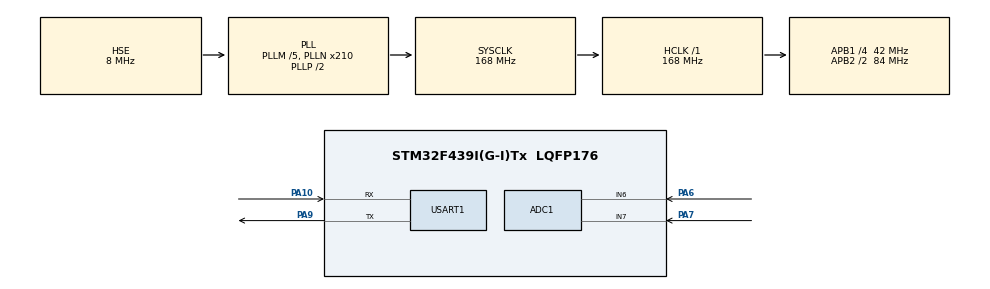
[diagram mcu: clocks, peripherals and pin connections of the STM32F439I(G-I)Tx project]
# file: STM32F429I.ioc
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ADC1.Channel-0\#ChannelRegularConversion=ADC_CHANNEL_6
ADC1.Channel-1\#ChannelRegularConversion=ADC_CHANNEL_7
ADC1.ClockPrescaler=ADC_CLOCKPRESCALER_PCLK_DIV4
ADC1.ContinuousConvMode=ENABLE
ADC1.DMAContinuousRequests=ENABLE
ADC1.DataAlign=ADC_DATAALIGN_RIGHT
ADC1.DiscontinuousConvMode=DISABLE
ADC1.EOCSelection=EOC_SINGLE_CONV
ADC1.EnableAnalogWatchDog=false
ADC1.ExternalTrigConvEdge=ADC_EXTERNALTRIGCONVEDGE_NONE
ADC1.InjNumberOfConversion=0
ADC1.NbrOfConversion=2
ADC1.NbrOfConversionFlag=1
ADC1.Rank-0\#ChannelRegularConversion=1
ADC1.Rank-1\#ChannelRegularConversion=2
ADC1.Resolution=ADC_RESOLUTION12b
ADC1.SamplingTime-0\#ChannelRegularConversion=ADC_SAMPLETIME_3CYCLES
ADC1.SamplingTime-1\#ChannelRegularConversion=ADC_SAMPLETIME_3CYCLES
ADC1.ScanConvMode=ENABLE
ADC1.master=1
Dma.ADC1.0.Channel=DMA_CHANNEL_0
Dma.ADC1.0.Direction=DMA_PERIPH_TO_MEMORY
Dma.ADC1.0.FIFOMode=DMA_FIFOMODE_DISABLE
Dma.ADC1.0.FIFOThreshold=DMA_FIFO_THRESHOLD_FULL
Dma.ADC1.0.Instance=DMA2_Stream0
Dma.ADC1.0.MemBurst=DMA_MBURST_SINGLE
Dma.ADC1.0.MemDataAlignment=DMA_MDATAALIGN_HALFWORD
Dma.ADC1.0.MemInc=DMA_MINC_ENABLE
Dma.ADC1.0.Mode=DMA_CIRCULAR
Dma.ADC1.0.PeriphBurst=DMA_PBURST_SINGLE
Dma.ADC1.0.PeriphDataAlignment=DMA_PDATAALIGN_HALFWORD
Dma.ADC1.0.PeriphInc=DMA_PINC_DISABLE
Dma.ADC1.0.Priority=DMA_PRIORITY_VERY_HIGH
Dma.Request0=ADC1
Mcu.Family=STM32F4
Mcu.Name=STM32F439I(G-I)Tx
Mcu.Package=LQFP176
NVIC.DMA2_Stream0_IRQn=true\:0\:0\:false
NVIC.PriorityGroup=NVIC_PRIORITYGROUP_4
PA10.Mode=Asynchronous
PA10.Signal=USART1_RX
PA6.Signal=ADCx_IN6
PA7.Signal=ADCx_IN7
PA9.Mode=Asynchronous
PA9.Signal=USART1_TX
PH0/OSC_IN.Mode=HSE-External-Oscillator
PH0/OSC_IN.Signal=RCC_OSC_IN
PH1/OSC_OUT.Mode=HSE-External-Oscillator
PH1/OSC_OUT.Signal=RCC_OSC_OUT
ProjectManager.TargetToolchain=MDK-ARM V5
RCC.48MHZClocksFreq_Value=84000000
RCC.AHBFreq_Value=168000000
RCC.APB1CLKDivider=RCC_HCLK_DIV4
RCC.APB1Freq_Value=42000000
RCC.APB1TimFreq_Value=84000000
RCC.APB2CLKDivider=RCC_HCLK_DIV2
RCC.APB2Freq_Value=84000000
RCC.APB2TimFreq_Value=168000000
RCC.CortexFreq_Value=168000000
RCC.HCLKFreq_Value=168000000
RCC.HSE_VALUE=8000000
RCC.HSI_VALUE=16000000
RCC.LSE_VALUE=32768
RCC.PLLM=5
RCC.PLLN=210
RCC.PLLSourceVirtual=RCC_PLLSOURCE_HSE
RCC.SYSCLKFreq_VALUE=168000000
RCC.SYSCLKSource=RCC_SYSCLKSOURCE_PLLCLK
RCC.VCOOutputFreq_Value=336000000
SH.ADCx_IN6.0=ADC1_IN6,IN6
SH.ADCx_IN7.0=ADC1_IN7,IN7
board=STM32F429I

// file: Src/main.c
/**
  ******************************************************************************
	*
  * File Name         	: main.c
  * Description        	: Main program body
	* Experimental 			: Flame Sensor                            	*
	* Connect      				: USART 1, PA9(TX)- RX TTL, PA10(RX)-TX TTL
  * 115200 BAUD, 8 Data Bits, None Parity, 1 Stop Bit, None Flow Control

	* Flame Sensor DOUT	- PA7
	* Flame Sensor AOUT	- PA6

  *******************************************************************************/

#include "stm32f4xx_hal.h"
#include "adc.h"
#include "dma.h"
#include "usart.h"
#include "gpio.h"
#include <math.h>

void SystemClock_Config(void);

/* USER CODE BEGIN PFP */
/* Private function prototypes -----------------------------------------------*/

/* USER CODE END PFP */

int main(void)
{

  /* USER CODE BEGIN 1 */
	uint16_t ADC_Value[100];
	  /* USER CODE END 1 */

  /* MCU Configuration----------------------------------------------------------*/

  /* Reset of all peripherals, Initializes the Flash interface and the Systick. */
  HAL_Init();

  /* Configure the system clock */
  SystemClock_Config();

  /* Initialize all configured peripherals */
  MX_GPIO_Init();
  MX_DMA_Init();
  MX_ADC1_Init();
  MX_USART1_UART_Init();

  /* USER CODE BEGIN 2 */
	/*##-1- Start the conversion process and enable interrupt ##################*/
  HAL_ADC_Start_DMA(&hadc1, (uint32_t*)&ADC_Value, 100);

  /* USER CODE END 2 */
	double AD_value;
  /* Infinite loop */
  /* USEdouble AD_value;R CODE BEGIN WHILE */
  while (1)
  {
  /* USER CODE END WHILE */

		HAL_ADC_Start(&hadc1);
		AD_value = HAL_ADC_GetValue(&hadc1);
		if(HAL_GPIO_ReadPin(GPIOA, GPIO_PIN_7) == GPIO_PIN_SET )
		{
			HAL_GPIO_WritePin(LED1_GPIO_Port, LED1_Pin,GPIO_PIN_RESET );
			printf("Flame Sensor no detected!\r\n");

		}
		else
		{
			HAL_GPIO_WritePin(LED1_GPIO_Port, LED1_Pin,GPIO_PIN_SET );
			printf("Flame Sensor detected\r\n");

    /* USER CODE BEGIN 3 */
  }

			float voltage = (AD_value / 4096.0) * 3;
			printf("ADC voltage = %2fV \r\n", voltage);
			HAL_Delay(20);   /* delay 2000ms */
}

}

/** System Clock Configuration
*/
void SystemClock_Config(void)
{

  RCC_OscInitTypeDef RCC_OscInitStruct;
  RCC_ClkInitTypeDef RCC_ClkInitStruct;

  __PWR_CLK_ENABLE();

  __HAL_PWR_VOLTAGESCALING_CONFIG(PWR_REGULATOR_VOLTAGE_SCALE1);

  RCC_OscInitStruct.OscillatorType = RCC_OSCILLATORTYPE_HSE;
  RCC_OscInitStruct.HSEState = RCC_HSE_ON;
  RCC_OscInitStruct.PLL.PLLState = RCC_PLL_ON;
  RCC_OscInitStruct.PLL.PLLSource = RCC_PLLSOURCE_HSE;
  RCC_OscInitStruct.PLL.PLLM = 5;
  RCC_OscInitStruct.PLL.PLLN = 210;
  RCC_OscInitStruct.PLL.PLLP = RCC_PLLP_DIV2;
  RCC_OscInitStruct.PLL.PLLQ = 4;
  HAL_RCC_OscConfig(&RCC_OscInitStruct);

  RCC_ClkInitStruct.ClockType = RCC_CLOCKTYPE_SYSCLK|RCC_CLOCKTYPE_PCLK1
                              |RCC_CLOCKTYPE_PCLK2;
  RCC_ClkInitStruct.SYSCLKSource = RCC_SYSCLKSOURCE_PLLCLK;
  RCC_ClkInitStruct.AHBCLKDivider = RCC_SYSCLK_DIV1;
  RCC_ClkInitStruct.APB1CLKDivider = RCC_HCLK_DIV4;
  RCC_ClkInitStruct.APB2CLKDivider = RCC_HCLK_DIV2;
  HAL_RCC_ClockConfig(&RCC_ClkInitStruct, FLASH_LATENCY_5);

  HAL_SYSTICK_Config(HAL_RCC_GetHCLKFreq()/1000);

  HAL_SYSTICK_CLKSourceConfig(SYSTICK_CLKSOURCE_HCLK);

  /* SysTick_IRQn interrupt configuration */
  HAL_NVIC_SetPriority(SysTick_IRQn, 0, 0);
}
